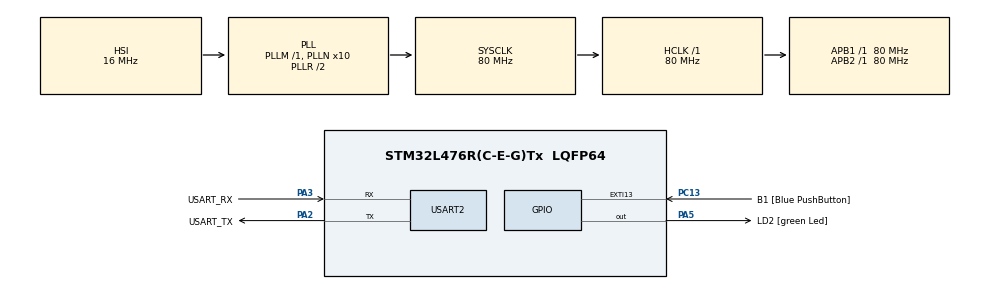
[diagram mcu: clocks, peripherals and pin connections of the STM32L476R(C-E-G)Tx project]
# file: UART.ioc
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Mcu.Family=STM32L4
Mcu.Name=STM32L476R(C-E-G)Tx
Mcu.Package=LQFP64
NVIC.PriorityGroup=NVIC_PRIORITYGROUP_4
NVIC.USART2_IRQn=true\:0\:0\:false\:false\:true
PA13.GPIO_Label=TMS
PA13.Signal=SYS_JTMS-SWDIO
PA14.GPIO_Label=TCK
PA14.Signal=SYS_JTCK-SWCLK
PA2.GPIO_Label=USART_TX
PA2.GPIO_Mode=GPIO_MODE_AF_PP
PA2.GPIO_PuPd=GPIO_NOPULL
PA2.GPIO_Speed=GPIO_SPEED_FREQ_VERY_HIGH
PA2.Mode=Asynchronous
PA2.Signal=USART2_TX
PA3.GPIO_Label=USART_RX
PA3.GPIO_Mode=GPIO_MODE_AF_PP
PA3.GPIO_PuPd=GPIO_NOPULL
PA3.GPIO_Speed=GPIO_SPEED_FREQ_VERY_HIGH
PA3.Mode=Asynchronous
PA3.Signal=USART2_RX
PA5.GPIO_Label=LD2 [green Led]
PA5.GPIO_ModeDefaultOutputPP=GPIO_MODE_OUTPUT_PP
PA5.GPIO_PuPd=GPIO_NOPULL
PA5.GPIO_Speed=GPIO_SPEED_FREQ_LOW
PA5.Signal=GPIO_Output
PB3.GPIO_Label=SWO
PB3.Signal=SYS_JTDO-SWO
PC13.GPIO_Label=B1 [Blue PushButton]
PC13.GPIO_ModeDefaultEXTI=GPIO_MODE_IT_FALLING
PC13.GPIO_PuPd=GPIO_NOPULL
PC13.Signal=GPXTI13
PC14/OSC32_IN.Signal=RCC_OSC32_IN
PC15/OSC32_OUT.Signal=RCC_OSC32_OUT
PH0/OSC_IN.Signal=RCC_OSC_IN
PH1/OSC_OUT.Signal=RCC_OSC_OUT
ProjectManager.HeapSize=0x200
ProjectManager.StackSize=0x400
ProjectManager.TargetToolchain=MDK-ARM V5
RCC.ADCFreq_Value=64000000
RCC.AHBFreq_Value=80000000
RCC.APB1Freq_Value=80000000
RCC.APB1TimFreq_Value=80000000
RCC.APB2Freq_Value=80000000
RCC.APB2TimFreq_Value=80000000
RCC.CortexFreq_Value=80000000
RCC.HCLKFreq_Value=80000000
RCC.HSE_VALUE=8000000
RCC.HSI_VALUE=16000000
RCC.LSE_VALUE=32768
RCC.MSI_VALUE=4000000
RCC.PLLN=10
RCC.PLLSourceVirtual=RCC_PLLSOURCE_HSI
RCC.PREFETCH_ENABLE=1
RCC.SYSCLKFreq_VALUE=80000000
RCC.SYSCLKSource=RCC_SYSCLKSOURCE_PLLCLK
RCC.USBFreq_Value=64000000
RCC.VCOOutputFreq_Value=160000000
USART2.WordLength=UART_WORDLENGTH_8B
board=NUCLEO-L476RG

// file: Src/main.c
/**
  ******************************************************************************
  * File Name          : main.c
  * Description        : Main program body
  ******************************************************************************
  *
  * COPYRIGHT(c) 2017 STMicroelectronics
  *
  * Redistribution and use in source and binary forms, with or without modification,
  * are permitted provided that the following conditions are met:
  *   1. Redistributions of source code must retain the above copyright notice,
  *      this list of conditions and the following disclaimer.
  *   2. Redistributions in binary form must reproduce the above copyright notice,
  *      this list of conditions and the following disclaimer in the documentation
  *      and/or other materials provided with the distribution.
  *   3. Neither the name of STMicroelectronics nor the names of its contributors
  *      may be used to endorse or promote products derived from this software
  *      without specific prior written permission.
  *
  * THIS SOFTWARE IS PROVIDED BY THE COPYRIGHT HOLDERS AND CONTRIBUTORS "AS IS"
  * AND ANY EXPRESS OR IMPLIED WARRANTIES, INCLUDING, BUT NOT LIMITED TO, THE
  * IMPLIED WARRANTIES OF MERCHANTABILITY AND FITNESS FOR A PARTICULAR PURPOSE ARE
  * DISCLAIMED. IN NO EVENT SHALL THE COPYRIGHT HOLDER OR CONTRIBUTORS BE LIABLE
  * FOR ANY DIRECT, INDIRECT, INCIDENTAL, SPECIAL, EXEMPLARY, OR CONSEQUENTIAL
  * DAMAGES (INCLUDING, BUT NOT LIMITED TO, PROCUREMENT OF SUBSTITUTE GOODS OR
  * SERVICES; LOSS OF USE, DATA, OR PROFITS; OR BUSINESS INTERRUPTION) HOWEVER
  * CAUSED AND ON ANY THEORY OF LIABILITY, WHETHER IN CONTRACT, STRICT LIABILITY,
  * OR TORT (INCLUDING NEGLIGENCE OR OTHERWISE) ARISING IN ANY WAY OUT OF THE USE
  * OF THIS SOFTWARE, EVEN IF ADVISED OF THE POSSIBILITY OF SUCH DAMAGE.
  *
  ******************************************************************************
  */
#include "main.h"
#include "stm32l4xx_hal.h"

UART_HandleTypeDef huart2;

/* USER CODE BEGIN PV */
/* Private variables ---------------------------------------------------------*/

/* USER CODE END PV */

void SystemClock_Config(void);
void Error_Handler(void);
static void MX_GPIO_Init(void);
static void MX_USART2_UART_Init(void);

/* USER CODE BEGIN PFP */

/** @brief Sends a character to serial port
 * @param ch Character to send
 * @retval Character sent
 */
int uartSendChar(int ch)
{
	HAL_UART_Transmit(&huart2, (uint8_t *)&ch, 1, HAL_MAX_DELAY);
  return ch;
}

/** @brief Receives a character from serial port
 * @param None
 * @retval Character received
 */
int uartReceiveChar(void)
{
  uint8_t ch;
	HAL_UART_Receive(&huart2, &ch, 1, HAL_MAX_DELAY);

  /* Echo character back to console */
	HAL_UART_Transmit(&huart2, &ch, 1, HAL_MAX_DELAY);

  /* And cope with Windows */
  if(ch == '\r'){
    uint8_t ret = '\n';
		HAL_UART_Transmit(&huart2, &ret, 1, HAL_MAX_DELAY);
  }

  return ch;
}

/**
 * @brief fputc call for standard output implementation
 * @param ch Character to print
 * @param f File pointer
 * @retval Character printed
 */
int fputc(int ch, FILE *f)
{
  return uartSendChar(ch);
}

/** @brief fgetc call for standard input implementation
 * @param f File pointer
 * @retval Character acquired from standard input
 */
int fgetc(FILE *f)
{
  return uartReceiveChar();
}

int main(void)
{
  /* USER CODE BEGIN 1 */
	char text[100];
	int num1, num2;
	int res;
  /* USER CODE END 1 */

  /* MCU Configuration----------------------------------------------------------*/

  /* Reset of all peripherals, Initializes the Flash interface and the Systick. */
  HAL_Init();

  /* Configure the system clock */
  SystemClock_Config();

  /* Initialize all configured peripherals */
  MX_GPIO_Init();
  MX_USART2_UART_Init();

  /* Infinite loop */
  /* USER CODE BEGIN WHILE */
  while (1)
  {
		printf("\f\n\rInsert a number: ");
		scanf("%d", &num1);
		printf("\n\rInsert a number: ");
		scanf("%d", &num2);
		res = num1 + num2;
		printf("\n\rResult: %d", res);
		printf("\n\rInsert a text: ");
		scanf("%s", text);
		printf("\n\rYou type %s", text);
  /* USER CODE END WHILE */

  }
}

/** System Clock Configuration
*/
void SystemClock_Config(void)
{

  RCC_OscInitTypeDef RCC_OscInitStruct;
  RCC_ClkInitTypeDef RCC_ClkInitStruct;
  RCC_PeriphCLKInitTypeDef PeriphClkInit;

    /**Initializes the CPU, AHB and APB busses clocks
    */
  RCC_OscInitStruct.OscillatorType = RCC_OSCILLATORTYPE_HSI;
  RCC_OscInitStruct.HSIState = RCC_HSI_ON;
  RCC_OscInitStruct.HSICalibrationValue = 16;
  RCC_OscInitStruct.PLL.PLLState = RCC_PLL_ON;
  RCC_OscInitStruct.PLL.PLLSource = RCC_PLLSOURCE_HSI;
  RCC_OscInitStruct.PLL.PLLM = 1;
  RCC_OscInitStruct.PLL.PLLN = 10;
  RCC_OscInitStruct.PLL.PLLP = RCC_PLLP_DIV7;
  RCC_OscInitStruct.PLL.PLLQ = RCC_PLLQ_DIV2;
  RCC_OscInitStruct.PLL.PLLR = RCC_PLLR_DIV2;
  if (HAL_RCC_OscConfig(&RCC_OscInitStruct) != HAL_OK)
  {
    Error_Handler();
  }

    /**Initializes the CPU, AHB and APB busses clocks
    */
  RCC_ClkInitStruct.ClockType = RCC_CLOCKTYPE_HCLK|RCC_CLOCKTYPE_SYSCLK
                              |RCC_CLOCKTYPE_PCLK1|RCC_CLOCKTYPE_PCLK2;
  RCC_ClkInitStruct.SYSCLKSource = RCC_SYSCLKSOURCE_PLLCLK;
  RCC_ClkInitStruct.AHBCLKDivider = RCC_SYSCLK_DIV1;
  RCC_ClkInitStruct.APB1CLKDivider = RCC_HCLK_DIV1;
  RCC_ClkInitStruct.APB2CLKDivider = RCC_HCLK_DIV1;

  if (HAL_RCC_ClockConfig(&RCC_ClkInitStruct, FLASH_LATENCY_4) != HAL_OK)
  {
    Error_Handler();
  }

  PeriphClkInit.PeriphClockSelection = RCC_PERIPHCLK_USART2;
  PeriphClkInit.Usart2ClockSelection = RCC_USART2CLKSOURCE_PCLK1;
  if (HAL_RCCEx_PeriphCLKConfig(&PeriphClkInit) != HAL_OK)
  {
    Error_Handler();
  }

    /**Configure the main internal regulator output voltage
    */
  if (HAL_PWREx_ControlVoltageScaling(PWR_REGULATOR_VOLTAGE_SCALE1) != HAL_OK)
  {
    Error_Handler();
  }

    /**Configure the Systick interrupt time
    */
  HAL_SYSTICK_Config(HAL_RCC_GetHCLKFreq()/1000);

    /**Configure the Systick
    */
  HAL_SYSTICK_CLKSourceConfig(SYSTICK_CLKSOURCE_HCLK);

  /* SysTick_IRQn interrupt configuration */
  HAL_NVIC_SetPriority(SysTick_IRQn, 0, 0);
}

/* USART2 init function */
static void MX_USART2_UART_Init(void)
{

  huart2.Instance = USART2;
  huart2.Init.BaudRate = 115200;
  huart2.Init.WordLength = UART_WORDLENGTH_8B;
  huart2.Init.StopBits = UART_STOPBITS_1;
  huart2.Init.Parity = UART_PARITY_NONE;
  huart2.Init.Mode = UART_MODE_TX_RX;
  huart2.Init.HwFlowCtl = UART_HWCONTROL_NONE;
  huart2.Init.OverSampling = UART_OVERSAMPLING_16;
  huart2.Init.OneBitSampling = UART_ONE_BIT_SAMPLE_DISABLE;
  huart2.AdvancedInit.AdvFeatureInit = UART_ADVFEATURE_NO_INIT;
  if (HAL_UART_Init(&huart2) != HAL_OK)
  {
    Error_Handler();
  }

}

/** Configure pins as
        * Analog
        * Input
        * Output
        * EVENT_OUT
        * EXTI
*/
static void MX_GPIO_Init(void)
{

  GPIO_InitTypeDef GPIO_InitStruct;

  /* GPIO Ports Clock Enable */
  __HAL_RCC_GPIOC_CLK_ENABLE();
  __HAL_RCC_GPIOH_CLK_ENABLE();
  __HAL_RCC_GPIOA_CLK_ENABLE();
  __HAL_RCC_GPIOB_CLK_ENABLE();

  /*Configure GPIO pin Output Level */
  HAL_GPIO_WritePin(LD2_GPIO_Port, LD2_Pin, GPIO_PIN_RESET);

  /*Configure GPIO pin : B1_Pin */
  GPIO_InitStruct.Pin = B1_Pin;
  GPIO_InitStruct.Mode = GPIO_MODE_IT_FALLING;
  GPIO_InitStruct.Pull = GPIO_NOPULL;
  HAL_GPIO_Init(B1_GPIO_Port, &GPIO_InitStruct);

  /*Configure GPIO pin : LD2_Pin */
  GPIO_InitStruct.Pin = LD2_Pin;
  GPIO_InitStruct.Mode = GPIO_MODE_OUTPUT_PP;
  GPIO_InitStruct.Pull = GPIO_NOPULL;
  GPIO_InitStruct.Speed = GPIO_SPEED_FREQ_LOW;
  HAL_GPIO_Init(LD2_GPIO_Port, &GPIO_InitStruct);

}

void Error_Handler(void)
{
  while(1)
  {
  }
}

/************************ (C) COPYRIGHT STMicroelectronics *****END OF FILE****/
